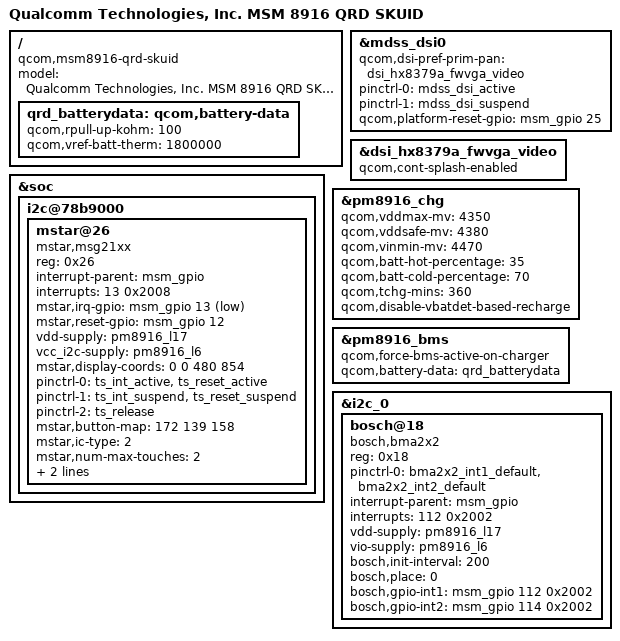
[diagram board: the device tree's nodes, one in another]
/* Copyright (c) 2014, The Linux Foundation. All rights reserved.
 *
 * This program is free software; you can redistribute it and/or modify
 * it under the terms of the GNU General Public License version 2 and
 * only version 2 as published by the Free Software Foundation.
 *
 * This program is distributed in the hope that it will be useful,
 * but WITHOUT ANY WARRANTY; without even the implied warranty of
 * MERCHANTABILITY or FITNESS FOR A PARTICULAR PURPOSE.  See the
 * GNU General Public License for more details.
 */

#include "msm8916-qrd-skui.dtsi"
#include "dsi-panel-hx8379a-fwvga-video.dtsi"

/ {
       model = "Qualcomm Technologies, Inc. MSM 8916 QRD SKUID";
       compatible = "qcom,msm8916-qrd-skuid", "qcom,msm8916-qrd", "qcom,msm8916", "qcom,qrd";
};

&mdss_dsi0 {
	qcom,dsi-pref-prim-pan = <&dsi_hx8379a_fwvga_video>;
	pinctrl-names = "mdss_default", "mdss_sleep";
	pinctrl-0 = <&mdss_dsi_active>;
	pinctrl-1 = <&mdss_dsi_suspend>;

	qcom,platform-reset-gpio = <&msm_gpio 25 0>;
};

&dsi_hx8379a_fwvga_video {
	qcom,cont-splash-enabled;
};

&soc {
	i2c@78b9000 { /* BLSP1 QUP5 */
		mstar@26 {
			compatible = "mstar,msg21xx";
			reg = <0x26>;
			interrupt-parent = <&msm_gpio>;
			interrupts = <13 0x2008>;
			mstar,irq-gpio = <&msm_gpio 13 0x00000001>;
			mstar,reset-gpio = <&msm_gpio 12 0x0>;
			vdd-supply = <&pm8916_l17>;
			vcc_i2c-supply = <&pm8916_l6>;
			mstar,display-coords = <0 0 480 854>;
			pinctrl-names = "pmx_ts_active","pmx_ts_suspend","pmx_ts_release";
			pinctrl-0 = <&ts_int_active &ts_reset_active>;
			pinctrl-1 = <&ts_int_suspend &ts_reset_suspend>;
			pinctrl-2 = <&ts_release>;
			mstar,button-map = <172 139 158>;
			mstar,ic-type = <2>;
			mstar,num-max-touches = <2>;
			mstar,hard-reset-delay-ms = <100>;
			mstar,post-hard-reset-delay-ms = <100>;
		};
	};
};

&pm8916_chg {
	qcom,vddmax-mv = <4350>;
	qcom,vddsafe-mv = <4380>;
	qcom,vinmin-mv = <4470>;
	qcom,batt-hot-percentage = <35>;
	qcom,batt-cold-percentage = <70>;
	qcom,tchg-mins = <360>;
	qcom,disable-vbatdet-based-recharge;
	status = "okay";
};

/ {
	qrd_batterydata: qcom,battery-data {
	qcom,rpull-up-kohm = <100>;
	qcom,vref-batt-therm = <1800000>;

	#include "batterydata-qrd-skuic-4v35-1850mah.dtsi"
	};
};

&pm8916_bms {
	status = "okay";
	qcom,force-bms-active-on-charger;
	qcom,battery-data = <&qrd_batterydata>;
};

&i2c_0 { /* BLSP1 QUP2 */
	bosch@18 { /* Accelerometer sensor */
		compatible = "bosch,bma2x2";
		reg = <0x18>;
		pinctrl-names = "default";
		pinctrl-0 = <&bma2x2_int1_default &bma2x2_int2_default>;
		interrupt-parent = <&msm_gpio>;
		interrupts = <112 0x2002>;
		vdd-supply = <&pm8916_l17>;
		vio-supply = <&pm8916_l6>;
		bosch,init-interval = <200>;
		bosch,place = <0>;
		bosch,gpio-int1 = <&msm_gpio 112 0x2002>;
		bosch,gpio-int2 = <&msm_gpio 114 0x2002>;
	};
};
